AUTOSAR XML (schema 4-2-2)
package /COM_SWC
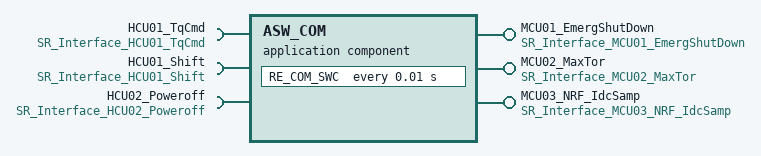
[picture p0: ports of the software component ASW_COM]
  application sw component type ASW_COM
    provide port MCU01_EmergShutDown: provided-interface=SR_Interface_MCU01_EmergShutDown
    provide port MCU02_MaxTor: provided-interface=SR_Interface_MCU02_MaxTor
    provide port MCU03_NRF_IdcSamp: provided-interface=SR_Interface_MCU03_NRF_IdcSamp
    require port HCU01_TqCmd: nonqueued-receiver-com-spec{alive-timeout=0.3, data-element=HCU01_Tq_Cmd, handle-timeout-type=REPLACE}, required-interface=SR_Interface_HCU01_TqCmd
    require port HCU01_Shift: nonqueued-receiver-com-spec{alive-timeout=0.3, data-element=HCU01_Shift, handle-timeout-type=REPLACE}, required-interface=SR_Interface_HCU01_Shift
    require port HCU02_Poweroff: nonqueued-receiver-com-spec{alive-timeout=0.3, data-element=HCU02_Poweroff, handle-timeout-type=REPLACE}, required-interface=SR_Interface_HCU02_Poweroff
    behavior IB_ASW_COM
      timing event TE_10ms_RE_COM_SWC: start-on-event=RE_COM_SWC, period=0.01
      runnable RE_COM_SWC
        data-receive-point-by-arguments:
          access RP_HCU01_TqCmd_HCU01_Tq_Cmd: accessed-variable=HCU01_TqCmd.HCU01_Tq_Cmd
          access RP_HCU01_Shift_HCU01_Shift: accessed-variable=HCU01_Shift.HCU01_Shift
          access RP_HCU02_Poweroff_HCU02_Poweroff: accessed-variable=HCU02_Poweroff.HCU02_Poweroff
        data-send-points:
          access SP_MCU01_EmergShutDown_MCU01_EmergShutDown: accessed-variable=MCU01_EmergShutDown.MCU01_EmergShutDown
          access SP_MCU02_MaxTor_MCU02_MaxTor: accessed-variable=MCU02_MaxTor.MCU02_MaxTor
          access SP_MCU03_NRF_IdcSamp_MCU03_NRF_IdcSamp: accessed-variable=MCU03_NRF_IdcSamp.MCU03_NRF_IdcSamp
